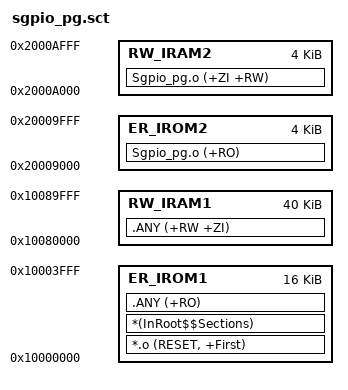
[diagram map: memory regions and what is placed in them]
; *************************************************************
; *** Scatter-Loading Description File generated by uVision ***
; *************************************************************

LR_IROM1 0x10000000 0x00004000  {    ; load region size_region
  ER_IROM1 0x10000000 0x00004000  {  ; load address = execution address
   *.o (RESET, +First)
   *(InRoot$$Sections)
   .ANY (+RO)
  }
  RW_IRAM1 0x10080000 0x0000A000  {  ; RW data
   .ANY (+RW +ZI)
  }
  RW_IRAM2 0x2000A000 0x00001000  {
    Sgpio_pg.o (+ZI +RW)
  }
}

LR_IROM2 0x20009000 0x00001000  {
  ER_IROM2 0x20009000 0x00001000  {  ; load address = execution address
    Sgpio_pg.o (+RO)
  }
}
